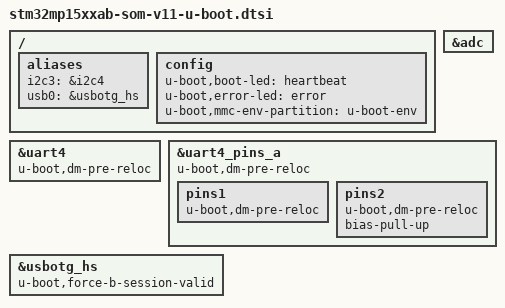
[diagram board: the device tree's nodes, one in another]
// SPDX-License-Identifier: GPL-2.0-or-later OR BSD-3-Clause
/*
 * Copyright : STMicroelectronics 2022
 */

#include "stm32mp15-scmi-u-boot.dtsi"

/ {
	aliases {
		i2c3 = &i2c4;
		usb0 = &usbotg_hs;
	};

	config {
		u-boot,boot-led = "heartbeat";
		u-boot,error-led = "error";
		u-boot,mmc-env-partition = "u-boot-env";
	};
};

&adc {
	status = "okay";
};

&uart4 {
	u-boot,dm-pre-reloc;
};

&uart4_pins_a {
	u-boot,dm-pre-reloc;
	pins1 {
		u-boot,dm-pre-reloc;
	};
	pins2 {
		u-boot,dm-pre-reloc;
		/* pull-up on rx to avoid floating level */
		bias-pull-up;
	};
};

&usbotg_hs {
	u-boot,force-b-session-valid;
};
